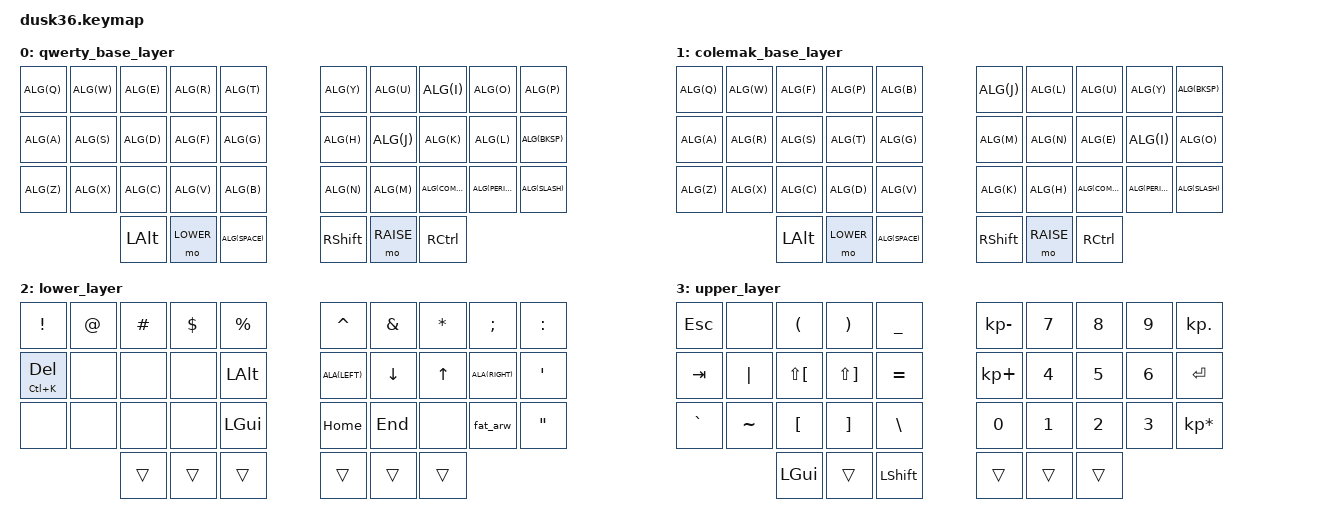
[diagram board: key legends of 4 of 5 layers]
#include <behaviors.dtsi>
#include <dt-bindings/zmk/keys.h>
#include <dt-bindings/zmk/outputs.h>

#define QWERTY_BASE  0
#define COLEMAK_BASE 1
#define LOWER        2
#define RAISE        3
#define ADJUST       4

#define ALG(keycode) &ht_tp LG(keycode) keycode    // Auto Left GUI Macro
#define ALA(keycode) &ht_tp LA(keycode) keycode    // Auto Left Alt Macro

/ {
    conditional_layers {
        compatible = "zmk,conditional-layers";
        tri_layer {
            if-layers = <LOWER RAISE>;
            then-layer = <ADJUST>;
        };
    };

    macros {
        fat_arw: fat_arrow {
            compatible = "zmk,behavior-macro";
            label = "FAT_ARROW";
            #binding-cells = <0>;
            wait-ms = <40>;
            tap-ms = <40>;
            bindings = <&kp EQUAL &kp GT>;
        };
    };

    behaviors {
        ht_tp: hold_tap_tap_preferred {
            compatible = "zmk,behavior-hold-tap";
            label = "HOLD_TAP_TAP_PREFERRED";
            #binding-cells = <2>;
            tapping-term-ms = <300>;
            quick-tap-ms = <250>;
            flavor = "tap-preferred";
            bindings = <&kp>, <&kp>;
        };
    };

    keymap {
        compatible = "zmk,keymap";

        qwerty_base_layer {
            bindings = <
                ALG(Q)  ALG(W)  ALG(E)    ALG(R)     ALG(T)            ALG(Y)      ALG(U)     ALG(I)      ALG(O)       ALG(P)
                ALG(A)  ALG(S)  ALG(D)    ALG(F)     ALG(G)            ALG(H)      ALG(J)     ALG(K)      ALG(L)       ALG(BKSP)
                ALG(Z)  ALG(X)  ALG(C)    ALG(V)     ALG(B)            ALG(N)      ALG(M)     ALG(COMMA)  ALG(PERIOD)  ALG(SLASH)
                                &kp LALT  &mo LOWER  ALG(SPACE)        &kp RSHIFT  &mo RAISE  &kp RCTRL
            >;
        };

        colemak_base_layer {
            bindings = <
                ALG(Q)  ALG(W)  ALG(F)    ALG(P)     ALG(B)            ALG(J)      ALG(L)     ALG(U)      ALG(Y)       ALG(BKSP)
                ALG(A)  ALG(R)  ALG(S)    ALG(T)     ALG(G)            ALG(M)      ALG(N)     ALG(E)      ALG(I)       ALG(O)
                ALG(Z)  ALG(X)  ALG(C)    ALG(D)     ALG(V)            ALG(K)      ALG(H)     ALG(COMMA)  ALG(PERIOD)  ALG(SLASH)
                                &kp LALT  &mo LOWER  ALG(SPACE)        &kp RSHIFT  &mo RAISE  &kp RCTRL
            >;
        };

        lower_layer {
            bindings = <
                &kp EXCL          &kp AT  &kp HASH  &kp DLLR  &kp PRCNT        &kp CARET  &kp AMPS  &kp STAR  &kp SEMI    &kp COLON
                &ht_tp LC(K) DEL  &none   &none     &none     &kp LALT         ALA(LEFT)  &kp DOWN  &kp UP    ALA(RIGHT)  &kp SQT
                &none             &none   &none     &none     &kp LGUI         &kp HOME   &kp END   &none     &fat_arw    &kp DQT
                                          &trans    &trans    &trans           &trans     &trans    &trans
            >;
        };

        upper_layer {
            bindings = <
                &kp ESC    &none      &kp LPAR      &kp RPAR      &kp UNDER         &kp KP_MINUS  &kp N7  &kp N8  &kp N9  &kp KP_DOT
                &kp TAB    &kp PIPE   &kp LS(LBKT)  &kp LS(RBKT)  &kp EQUAL         &kp KP_PLUS   &kp N4  &kp N5  &kp N6  &kp ENTER
                &kp GRAVE  &kp TILDE  &kp LBKT      &kp RBKT      &kp BSLH          &kp N0        &kp N1  &kp N2  &kp N3  &kp KP_MULTIPLY
                                      &kp LGUI      &trans        &kp LSHIFT        &trans        &trans     &trans
            >;
        };

        adjust_layer {
            bindings = <
                &tog COLEMAK_BASE  &none  &none  &none   &none        &none  &kp LC(LA(LG(LEFT)))  &kp LC(LA(ENTER))  &kp LC(LA(LG(RIGHT)))  &none
                &none              &none  &none  &none   &none        &none  &kp LC(LA(LEFT))      &kp LC(LA(DOWN))   &kp LC(LA(RIGHT))      &none
                &none              &none  &none  &none   &none        &none  &none                 &none                  &none              &none
                                          &none  &trans  &none        &none  &trans                &none
            >;
        };
    };
};
